# FAULTMUX register map
Vendor: Texas Instruments
Peripheral module from a debugger description file (folder UCD3138R032RSM).
Registers are 32-bit, access per field, no defined reset value unless marked. A register's access mark holds for its fields unless they carry their own. Offsets are as the file gives them; lines under a group give offsets from that group; [hi:lo] are bit positions; {n}, {i} and the like mark numbered series; 'fields as' and 'values as' point back to an identical list; <NAME> marks a mode.

## FAULTMUX (part 1 of 2) — top level module
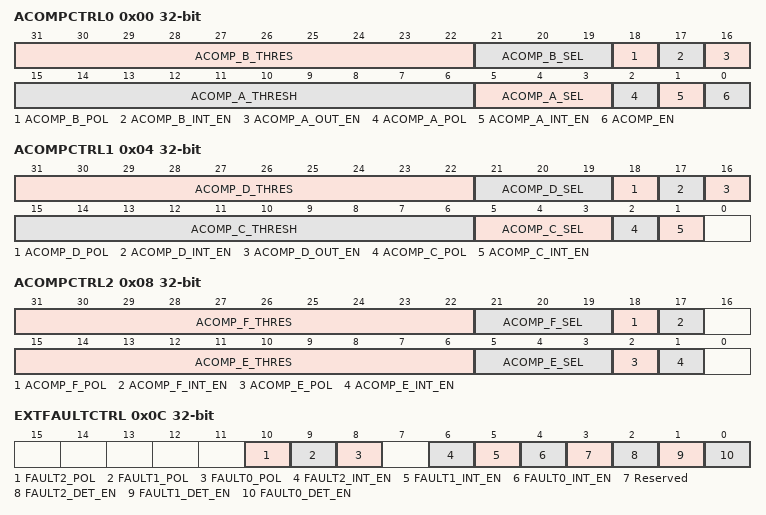
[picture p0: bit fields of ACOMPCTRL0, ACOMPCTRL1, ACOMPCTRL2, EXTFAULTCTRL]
0x00 ACOMPCTRL0 rw — Analog Comparator Control 0 Register
  [31:22] ACOMP_B_THRES — Configures Analog Comparator B Threshold value.Multiplies refernece voltage 19.53125 mV to (ACOMP_B_THRES+1)
  [21:19] ACOMP_B_SEL — Configures Analog Comparator B Threshold
    4=filter2 (Analog Comparator B Threshold set by Filter 2 Output); 3=filter1 (Analog Comparator B Threshold set by Filter 1 Output); 2=filter0 (Analog Comparator B Threshold set by Filter 0 Output); 1=comp_ramp (Analog Comparator B Threshold set by Comparator Ramp 0); 0=Default (Analog Comparator B Threshold set by ACOMP_B_THRESH (Default))
  [18] ACOMP_B_POL — Analog Comparator B Polarity
    1=Above_threshold (Comparator result enabled when input exceeds threshold (Default)); 0=Below_threshold (Comparator result enabled when input falls below threshold)
  [17] ACOMP_B_INT_EN — Analog Comparator B Interrupt Enable
    1=Enables analog comparator B interrupt generation; 0=Disables analog comparator B interrupt generation
  [16] ACOMP_A_OUT_EN — Analog Comparator A DAC Output Enable
    1=Enables output of comparator DAC A onto EAP2 pin; 0=Disables output of comparator DAC A onto EAP2 pin
  [15:6] ACOMP_A_THRESH — Configures Analog Comparator A Threshold value.Multiplies refernece voltage 19.53125 mV to (ACOMP_B_THRES+1)
  [5:3] ACOMP_A_SEL — Configures Analog Comparator A Threshold
    4=filter2 (Analog Comparator A Threshold set by Filter 2 Output); 3=filter1 (Analog Comparator A Threshold set by Filter 1 Output); 2=filter0 (Analog Comparator A Threshold set by Filter 0 Output); 1=comp_ramp (Analog Comparator A Threshold set by Comparator Ramp 0); 0=Default (Analog Comparator A Threshold set by ACOMP_B_THRESH (Default))
  [2] ACOMP_A_POL — Analog Comparator A Polarity
    values as ACOMP_B_POL
  [1] ACOMP_A_INT_EN — Analog Comparator A Interrupt Enable
    1=Enables Analog Comparator A Interrupt generation; 0=diable (Disables Analog Comparator A Interrupt generation (Default))
  [0] ACOMP_EN — Analog Comparators Enable
    1=enable (Analog Comparators Enabled); 0=diable (Analog Comparators Disabled (Default))
0x04 ACOMPCTRL1 — Analog Comparator Control 1 Register
  [31:22] ACOMP_D_THRES rw — Configures Analog Comparator D Threshold value.Multiplies refernece voltage 19.53125 mV to (ACOMP_B_THRES+1)
  [21:19] ACOMP_D_SEL rw — Configures Analog Comparator D Threshold
    4=filter2 (Analog Comparator D Threshold set by Filter 2 Output); 3=filter1 (Analog Comparator D Threshold set by Filter 1 Output); 2=filter0 (Analog Comparator D Threshold set by Filter 0 Output); 1=comp_ramp (Analog Comparator D Threshold set by Comparator Ramp 0); 0=Default (Analog Comparator D Threshold set by ACOMP_D_THRESH (Default))
  [18] ACOMP_D_POL rw — Analog Comparator D Polarity
    values as ACOMPCTRL0.ACOMP_B_POL
  [17] ACOMP_D_INT_EN rw — Analog Comparator D Interrupt Enable
    1=Enables Analog Comparator D Interrupt generation; 0=diable (Disables Analog Comparator D Interrupt generation (Default))
  [16] ACOMP_D_OUT_EN rw — Analog Comparator D DAC Output Enable
    1=Enables output of Comparator DAC D onto AD pin; 0== Disables output of Comparator DAC D onto AD pin (Default)
  [15:6] ACOMP_C_THRESH rw — Configures Analog Comparator C Threshold value.Multiplies refernece voltage 19.53125 mV to (ACOMP_C_THRES+1)
  [5:3] ACOMP_C_SEL rw — Configures Analog Comparator C Threshold
    4=filter2 (Analog Comparator C Threshold set by Filter 2 Output); 3=filter1 (Analog Comparator C Threshold set by Filter 1 Output); 2=filter0 (Analog Comparator C Threshold set by Filter 0 Output); 1=comp_ramp (Analog Comparator C Threshold set by Comparator Ramp 0); 0=Default (Analog Comparator C Threshold set by ACOMP_C_THRESH (Default))
  [2] ACOMP_C_POL rw — Analog Comparator C Polarity
    values as ACOMPCTRL0.ACOMP_B_POL
  [1] ACOMP_C_INT_EN rw — Analog Comparator C Interrupt Enable
    1=Enables Analog Comparator C Interrupt generation; 0=diable (Disables Analog Comparator C Interrupt generation (Default))
0x08 ACOMPCTRL2 — Analog Comparator Control 1 Register
  [31:22] ACOMP_F_THRES rw — Configures Analog Comparator F Threshold value.Multiplies refernece voltage 19.53125 mV to (ACOMP_F_THRES+1)
    1=refrence_voltage_2 (= Comparator Reference of 39.0625 mV); 0=refrence_voltage (= Comparator Reference of 19.53125 mV)
  [21:19] ACOMP_F_SEL rw — Configures Analog Comparator F Threshold
    5=AD05_pin (Reference driven from AD05 pin instead of DAC); 4=filter2 (Analog Comparator F Threshold set by Filter 2 Output); 3=filter1 (Analog Comparator F Threshold set by Filter 1 Output); 2=filter0 (Analog Comparator F Threshold set by Filter 0 Output); 1=comp_ramp (Analog Comparator F Threshold set by Comparator Ramp 0); 0=Default (Analog Comparator F Threshold set by ACOMP_F_THRESH (Default))
  [18] ACOMP_F_POL rw — Analog Comparator F Polarity
    values as ACOMPCTRL0.ACOMP_B_POL
  [17] ACOMP_F_INT_EN rw — Analog Comparator F Interrupt Enable
    1=Enables Analog Comparator F Interrupt generation; 0=diable (Disables Analog Comparator F Interrupt generation (Default))
  [15:6] ACOMP_E_THRES rw — Configures Analog Comparator E Threshold value.Multiplies refernece voltage 19.53125 mV to (ACOMP_E_THRES+1)
    values as ACOMP_F_THRES
  [5:3] ACOMP_E_SEL rw — Configures Analog Comparator E Threshold
    4=filter2 (Analog Comparator E Threshold set by Filter 2 Output); 3=filter1 (Analog Comparator E Threshold set by Filter 1 Output); 2=filter0 (Analog Comparator E Threshold set by Filter 0 Output); 1=comp_ramp (Analog Comparator E Threshold set by Comparator Ramp 0); 0=Default (Analog Comparator E Threshold set by ACOMP_E_THRESH (Default))
  [2] ACOMP_E_POL rw — Analog Comparator E Polarity
    values as ACOMPCTRL0.ACOMP_B_POL
  [1] ACOMP_E_INT_EN rw — Analog Comparator E Interrupt Enable
    1=Enables Analog Comparator E Interrupt generation; 0=diable (Disables Analog Comparator E Interrupt generation (Default))
0x0C EXTFAULTCTRL — External Fault Control Register
  [10] FAULT2_POL rw — Polarity configuration for FAULT[2] pin
    1=rising (Fault detection enabled on rising edge (Default)); 0=falling (Fault detection enabled on falling edg)
  [9] FAULT1_POL rw — Polarity configuration for FAULT[1] pin
    values as FAULT2_POL
  [8] FAULT0_POL rw — Polarity configuration for FAULT[0] pin
    values as FAULT2_POL
  [6] FAULT2_INT_EN rw — FAULT[2] Pin Interrupt Enable
    1=Enables Fault Detection Interrupt generation; 0=Disables Fault Detection Interrupt generation (Default)
  [5] FAULT1_INT_EN rw — FAULT[1] Pin Interrupt Enable
    values as FAULT2_INT_EN
  [4] FAULT0_INT_EN rw — FAULT[0] Pin Interrupt Enable
    values as FAULT2_INT_EN
  [3] Reserved ro — FAULT[3] Pin Detection Enable
    1=enable (Fault Detection Enabled); 0=disable (Fault Detection Disabled (Default))
  [2] FAULT2_DET_EN rw — FAULT[2] Pin Detection Enable
    values as Reserved
  [1] FAULT1_DET_EN rw — FAULT[1] Pin Detection Enable
    values as Reserved
  [0] FAULT0_DET_EN rw — FAULT[0] Pin Detection Enable
    values as Reserved
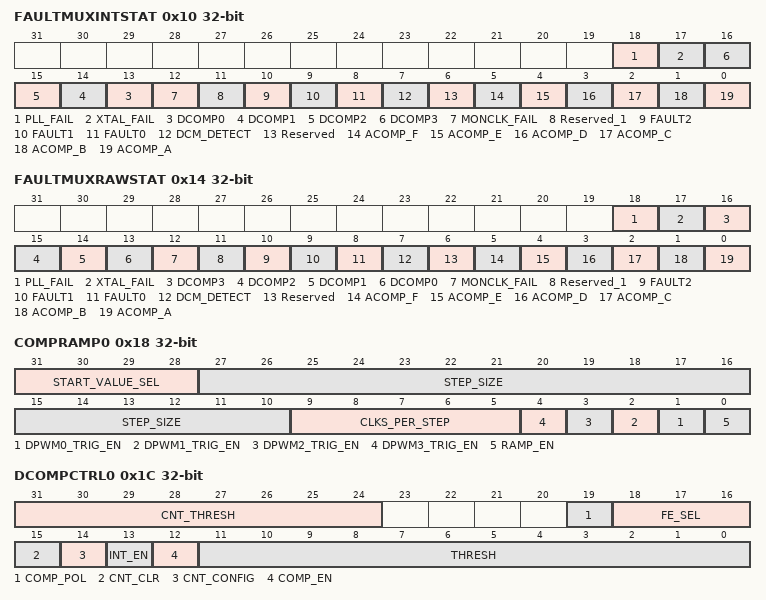
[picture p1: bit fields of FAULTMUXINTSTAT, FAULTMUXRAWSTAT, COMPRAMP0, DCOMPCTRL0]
0x10 FAULTMUXINTSTAT ro — Fault Mux Interrupt Status Register
  [18] PLL_FAIL
    1=detected (PLL failure detected); 0=undetected (PLL failure not detected)
  [17] XTAL_FAIL
    1=detected (XTAL failure detected); 0=notdetected (XTAL failure not detected)
  [n+13] DCOMP{n} (n=0..3) — Digital Comparator {n} Interrupt Status, cleared by read of status register
    1=active (Comparator threshold interrupt active); 0=inactive (Comparator threshold interrupt inactive)
  [12] MONCLK_FAIL — Monitor Oscillator Failure Interrupt Status, cleared by read of status register
    1=failure (Low Frequency Oscillator failure detected); 0=operational (Low Frequency Oscillator operational)
  [11] Reserved_1 — External FAULT[3] Interrupt Detection
    1=found (External GPIO detection found); 0=notfound (No External GPIO detection found)
  [10] FAULT2 — External FAULT[2] Interrupt Detection
    values as Reserved_1
  [9] FAULT1 — External FAULT[1] Interrupt Detection
    values as Reserved_1
  [8] FAULT0 — External FAULT[0] Interrupt Detection
    values as Reserved_1
  [7] DCM_DETECT — Discontinuous Conduction Mode Interrupt Status, cleared by read of status registe
    1=notdetcted (Discontinuous Conduction Mode not detected); 0=detected (Discontinuous Conduction Mode detected)
  [6] Reserved — Analog Comparator G Interrupt Status, cleared by read of status register
    values as DCOMP0
  [5] ACOMP_F — Analog Comparator F Interrupt Status, cleared by read of status register
    values as DCOMP0
  [4] ACOMP_E — Analog Comparator E Interrupt Status, cleared by read of status register
    values as DCOMP0
  [3] ACOMP_D — Analog Comparator D Interrupt Status, cleared by read of status register
    values as DCOMP0
  [2] ACOMP_C — Analog Comparator C Interrupt Status, cleared by read of status register
    values as DCOMP0
  [1] ACOMP_B — Analog Comparator B Interrupt Status, cleared by read of status register
    values as DCOMP0
  [0] ACOMP_A — Analog Comparator A Interrupt Status, cleared by read of status register
    values as DCOMP0
0x14 FAULTMUXRAWSTAT ro — Fault Mux Raw Status Register
  [18] PLL_FAIL — PLL fail raw status
    1=detected (PLL failure detected); 0=notdetected (PLL failure not detected)
  [17] XTAL_FAIL — XTAL fail raw status
    values as FAULTMUXINTSTAT.XTAL_FAIL
  [16] DCOMP3 — Digital Comparator 3 Raw Status
    1=exceeded (Comparator threshold exceeded); 0=notexceeded (Comparator threshold not exceeded)
  [15] DCOMP2 — Digital Comparator 2 Raw Status
    values as DCOMP3
  [14] DCOMP1 — Digital Comparator 2 Raw Status
    values as DCOMP3
  [13] DCOMP0 — Digital Comparator 0 Raw Status
    values as DCOMP3
  [12] MONCLK_FAIL — Monitor Oscillator Failure Raw Status
    1=failure (Monitor Oscillator failure detected); 0=operational (Monitor Oscillator operational)
  [11] Reserved_1 — External Fault Detection on FAULT[3] pin
    1=found (External GPIO detection found); 0=notfound (No External FAULT[3] detection found)
  [10] FAULT2 — External Fault Detection on FAULT[2] pin
    1=found (External GPIO detection found); 0=notfound (No External FAULT[2] detection found)
  [9] FAULT1 — External Fault Detection on FAULT[1] pin
    1=found (External GPIO detection found); 0=notfound (No External FAULT[1] detection found)
  [8] FAULT0 — External Fault Detection on FAULT[8] pin
    1=found (External GPIO detection found); 0=notfound (No External FAULT[8] detection found)
  [7] DCM_DETECT — Discontinuous Conduction Mode Raw Status
    values as FAULTMUXINTSTAT.DCM_DETECT
  [6] Reserved — Analog Comparator G Raw Result
    1=exceeded (Comparator threshold not exceeded); 0=notexceeded (Comparator threshold not exceeded)
  [5] ACOMP_F — Analog Comparator F Raw Result
    values as Reserved
  [4] ACOMP_E — Analog Comparator E Raw Result
    values as Reserved
  [3] ACOMP_D — Analog Comparator D Raw Result
    values as Reserved
  [2] ACOMP_C — Analog Comparator C Raw Result
    values as Reserved
  [1] ACOMP_B — Analog Comparator B Raw Result
    values as Reserved
  [0] ACOMP_A — Analog Comparator A Raw Result
    values as Reserved
0x18 COMPRAMP0 rw — Comparator Ramp Control 0 Register
  [31:28] START_VALUE_SEL — Configures comparator ramp starting value
    9=acomp_G (Analog Comparator Threshold G Value); 8=acomp_F (Analog Comparator Threshold F Value); 7=acomp_E (Analog Comparator Threshold E Value); 6=acomp_D (Analog Comparator Threshold D Value); 5=acomp_C (Analog Comparator Threshold C Value); 4=acomp_B (Analog Comparator Threshold B Value); 3=acomp_A (Analog Comparator Threshold A Value); 2=filter2 (Filter 1 Output (Bits 17-11)); 1=Filter 1 Output (Bits 17-11); 0=FILTER0 (Filter 0 Output (Bits 17-11) (Default))
  [27:10] STEP_SIZE — Programmable 18-bit unsigned comparator step with Bits 27:24 representing the integer portion of the comparator step (0-15 Comparator steps of 19.5mV each) and Bits 23:10 representing the fractional portion of the comparator step
  [9:5] CLKS_PER_STEP — Selects number of ICLK or (ICLK/2) clock cycles per comparator step where number of subcycles can vary from 1 to 32
  [n+1] DPWM{n}_TRIG_EN (n=0..3) — Enables DPWM Trigger from DPWM {n} to Analog Comparator Ramp 0
    1=routed (DPWM {n} trigger routed to Analog Comparator Ramp 0); 0=not_routed (DPWM {n} trigger not routed to Analog Comparator Ramp 0 (Default))
  [0] RAMP_EN — Enable for Analog Comparator Ramp 0
    1=enable (Analog Comparator Ramp enabled); 0=disabled (Analog Comparator Ramp disabled (Default))
0x1C DCOMPCTRL0 — Digital Comparator Control 0 Register
  [31:24] CNT_THRESH rw — Sets the number of received comparator events before declaring a fault
  [19] COMP_POL rw — Digital Comparator 0 Polarity
    1=above (Digital Comparator result asserted if value above threshold (Default)); 0=below (Digital Comparator result asserted if value below threshold (Default))
  [18:16] FE_SEL rw — Selects which Front End absolute data is used for Digital Comparison with threshold
    5=Front End 2 error data selected; 4=Front End 1 error data selected; 3=Front End 0 error data selected; 2=Front End 2 absolute data selected; 1=Front End 1 absolute data selected; 0=Front End 0 absolute data selected (Default)
  [15] CNT_CLR rw — Comparator Detection Counter clear
    1=Clear Comparator Detection counter and associated fault; 0=No clear of Comparator Detection Counter (Default)
  [14] CNT_CONFIG rw — Comparator Detection Counter configuration
    1=decrements (Counter decrements by 1 upon receipt of sample which does not exceed comparator threshold); 0=clear (Counter clears upon receipt of sample which does not exceed comparator threshold (Default))
  [13] INT_EN rw — Comparator Interrupt Enable
    1=Enables Comparator Interrupt generation; 0=Disables Comparator Interrupt generation (Default)
  [12] COMP_EN rw — Digital Comparator 0 Enable
    1=Enables Digital Comparator 0; 0=Disables Digital Comparator 0 (Default)
  [11:0] THRESH rw — Sets the digital comparator threshold, 12-bit signed value with resolution of 1mV/bit
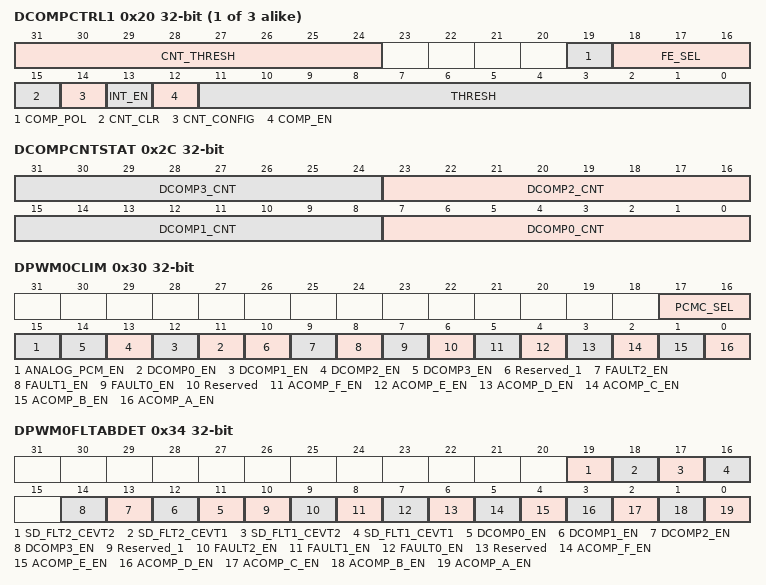
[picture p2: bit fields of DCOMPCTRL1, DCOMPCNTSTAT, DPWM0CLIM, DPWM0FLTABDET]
{0x1C+4i} DCOMPCTRL{i} (i=1..3) — Digital Comparator Control {i} Register
  [31:24] CNT_THRESH rw — Sets the number of received comparator events before declaring a fault
  [19] COMP_POL rw — Digital Comparator {i} Polarity
    values as DCOMPCTRL0.COMP_POL
  [18:16] FE_SEL rw — Selects which Front End absolute data is used for Digital Comparison with threshold
    values as DCOMPCTRL0.FE_SEL
  [15] CNT_CLR rw — Comparator Detection Counter clear
    values as DCOMPCTRL0.CNT_CLR
  [14] CNT_CONFIG rw — Comparator Detection Counter configuration
    values as DCOMPCTRL0.CNT_CONFIG
  [13] INT_EN rw — Comparator Interrupt Enable
    values as DCOMPCTRL0.INT_EN
  [12] COMP_EN rw — Digital Comparator {i} Enable
    1=Enables Digital Comparator {i}; 0=Disables Digital Comparator {i} (Default)
  [11:0] THRESH rw — Sets the digital comparator threshold, 12-bit signed value with resolution of 1.5625mV/bit
0x2C DCOMPCNTSTAT ro — Digital Comparator Counter Status Register
  [8n+7:8n] DCOMP{n}_CNT (n=0..3) — Current value of Digital Comparator {n} detection counter
0x30 DPWM0CLIM — DPWM_0 Current Limit Control Register
  [17:16] PCMC_SEL rw — Selects the PCMC module to trigger PCMC-CBC fault
    2=PCMC3; 1=PCMC2; 0=PCMC1
  [15] ANALOG_PCM_EN rw — Enables Analog Peak Current detection result for DPWM_0 Current Limit
    1=enabled (Analog Peak Current detection enabled for current limit); 0=disabled (Analog Peak Current detection disabled for current limit (Default))
  [n+11] DCOMP{n}_EN rw (n=0..3) — Enables Digital Comparator {n} result for DPWM_0 Current Limit
    values as ANALOG_PCM_EN
  [10] Reserved_1 ro — Enables FAULT[3] pin for DPWM_0 Current Limit
    1=enabled (External Fault pin enabled for current limit); 0=disabled (External Fault pin disabled for current limit (Default))
  [9] FAULT2_EN rw — Enables FAULT[2] pin for DPWM_0 Current Limit
    values as Reserved_1
  [8] FAULT1_EN rw — Enables FAULT[1] pin for DPWM_0 Current Limit
    values as Reserved_1
  [7] FAULT0_EN rw — Enables FAULT[0] pin for DPWM_0 Current Limit
    values as Reserved_1
  [6] Reserved ro — Enables Analog Comparator G result for DPWM_0 Current Limit
    1=enabled (Analog Comparator result enabled for current limit); 0=disabled (Analog Comparator result disabled for current limit (Default))
  [5] ACOMP_F_EN rw — Enables Analog Comparator F result for DPWM_0 Current Limit
    values as Reserved
  [4] ACOMP_E_EN rw — Enables Analog Comparator E result for DPWM_0 Current Limit
    values as Reserved
  [3] ACOMP_D_EN rw — Enables Analog Comparator D result for DPWM_0 Current Limit
    values as Reserved
  [2] ACOMP_C_EN rw — Enables Analog Comparator C result for DPWM_0 Current Limit
    values as Reserved
  [1] ACOMP_B_EN rw — Enables Analog Comparator B result for DPWM_0 Current Limit
    values as Reserved
  [0] ACOMP_A_EN rw — Enables Analog Comparator A result for DPWM_0 Current Limit
    values as Reserved
0x34 DPWM0FLTABDET — DPWM_0 Fault AB Detection Register
  [19] SD_FLT2_CEVT2 rw — Enables SDFM Filter2 Compare Event 2 output for DPWM1 Fault detection
  [18] SD_FLT2_CEVT1 rw — Enables SDFM Filter2 Compare Event 1 output for DPWM1 Fault detection
  [17] SD_FLT1_CEVT2 rw — Enables SDFM Filter1 Compare Event 2 output for DPWM1 Fault detection
  [16] SD_FLT1_CEVT1 rw — Enables SDFM Filter1 Compare Event 1 output for DPWM1 Fault detection
  [n+11] DCOMP{n}_EN rw (n=0..3) — Enables Digital Comparator {n} result for DPWM_0 Fault AB Detection
    1=enable (Digital Comparator {n} result enabled for current limit); 0=disable (Digital Comparator {n} result disabled for current limit (Default))
  [10] Reserved_1 ro — Enables FAULT[3] pin for DPWM_0 Current Limit
    1=enable (External Fault pin enabled for current limit); 0=disable (External Fault pin disabled for current limit (Default))
  [9] FAULT2_EN rw — Enables FAULT[2] pin for DPWM_0 Fault AB Detection
    values as Reserved_1
  [8] FAULT1_EN rw — Enables FAULT[1] pin for DPWM_0 Fault AB Detection
    values as Reserved_1
  [7] FAULT0_EN rw — Enables FAULT[0] pin for DPWM_0 Fault AB Detection
    values as Reserved_1
  [6] Reserved ro — Enables Analog Comparator G result for DPWM_0 Current Limit
    1=enable (Analog Comparator result enabled for current limit); 0=disable (Analog Comparator result disabled for current limit (Default))
  [5] ACOMP_F_EN rw — Enables Analog Comparator F result for DPWM_0 Fault AB Detection
    values as Reserved
  [4] ACOMP_E_EN rw — Enables Analog Comparator E result for DPWM_0 Fault AB Detection
    values as Reserved
  [3] ACOMP_D_EN rw — Enables Analog Comparator D result for DPWM_0 Fault AB Detection
    values as Reserved
  [2] ACOMP_C_EN rw — Enables Analog Comparator C result for DPWM_0 Fault AB Detection
    values as Reserved
  [1] ACOMP_B_EN rw — Enables Analog Comparator B result for DPWM_0 Fault AB Detection
    values as Reserved
  [0] ACOMP_A_EN rw — Enables Analog Comparator A result for DPWM_0 Fault AB Detection
    values as Reserved
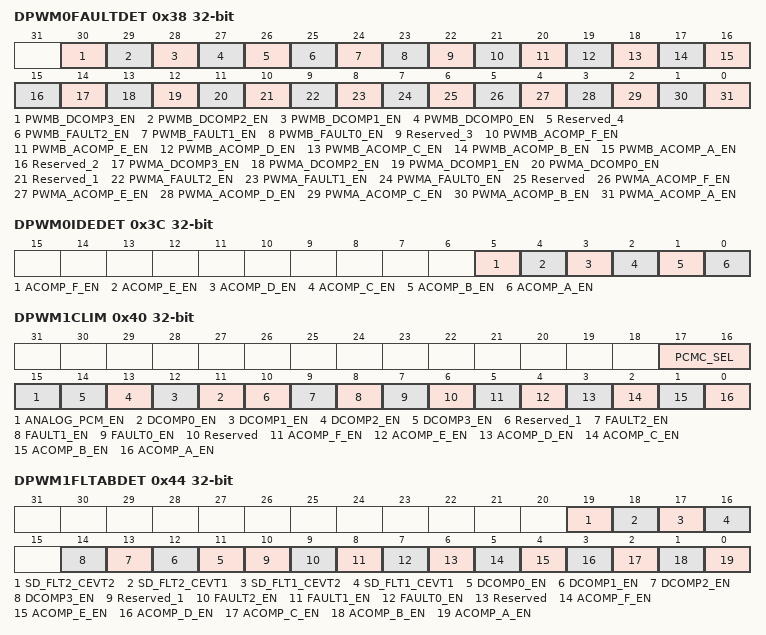
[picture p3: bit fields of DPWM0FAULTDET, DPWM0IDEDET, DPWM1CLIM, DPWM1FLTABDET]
0x38 DPWM0FAULTDET — DPWM 0 Fault Detection Register
  [30] PWMB_DCOMP3_EN rw — Enables Digital Comparator 3 result for DPWM_0 PWM-B Fault Detection
    1=enable (Digital Comparator 3 enabled for fault detection); 0=disbaled (Digital Comparator 3 disabled for fault detection (Default))
  [29] PWMB_DCOMP2_EN rw — Enables Digital Comparator 2 result for DPWM_0 PWM-B Fault Detection
    1=enable (Digital Comparator 2 enabled for fault detection); 0=disbaled (Digital Comparator 2 disabled for fault detection (Default))
  [28] PWMB_DCOMP1_EN rw — Enables Digital Comparator 1 result for DPWM_0 PWM-B Fault Detection
    1=enable (Digital Comparator 1 enabled for fault detection); 0=disbaled (Digital Comparator 1 disabled for fault detection (Default))
  [27] PWMB_DCOMP0_EN rw — Enables Digital Comparator 3 result for DPWM_0 PWM-B Fault Detection
    values as PWMB_DCOMP3_EN
  [26] Reserved_4 ro — Enables FAULT[3] pin for DPWM_0 PWM-B Fault Detection
    1=enable (External Fault pin enabled for fault detection); 0=disbaled (External Fault pin disabled for fault detection (Default))
  [25] PWMB_FAULT2_EN rw — Enables FAULT[2] pin for DPWM_0 PWM-B Fault Detection
    values as Reserved_4
  [24] PWMB_FAULT1_EN rw — Enables FAULT[1] pin for DPWM_0 PWM-B Fault Detection
    values as Reserved_4
  [23] PWMB_FAULT0_EN rw — Enables FAULT[0] pin for DPWM_0 PWM-B Fault Detection
    values as Reserved_4
  [22] Reserved_3 ro — Enables Analog Comparator G result for DPWM_0 PWM-B Fault detection
    1=enable (Analog Comparator result enabled for fault detection); 0=disbaled (Analog Comparator result disabled for fault detection (Default))
  [21] PWMB_ACOMP_F_EN rw — Enables Analog Comparator F result for DPWM_0 PWM-B Fault detection
    values as Reserved_3
  [20] PWMB_ACOMP_E_EN rw — Enables Analog Comparator E result for DPWM_0 PWM-B Fault detection
    values as Reserved_3
  [19] PWMB_ACOMP_D_EN rw — Enables Analog Comparator D result for DPWM_0 PWM-B Fault detection
    values as Reserved_3
  [18] PWMB_ACOMP_C_EN rw — Enables Analog Comparator C result for DPWM_0 PWM-B Fault detection
    values as Reserved_3
  [17] PWMB_ACOMP_B_EN rw — Enables Analog Comparator B result for DPWM_0 PWM-B Fault detection
    values as Reserved_3
  [16] PWMB_ACOMP_A_EN rw — Enables Analog Comparator A result for DPWM_0 PWM-B Fault detection
    values as Reserved_3
  [15] Reserved_2 ro — RESEVED
  [14] PWMA_DCOMP3_EN rw — Enables Digital Comparator 3 result for DPWM_0 PWM-A Fault Detection
    values as PWMB_DCOMP3_EN
  [13] PWMA_DCOMP2_EN rw — Enables Digital Comparator 2 result for DPWM_0 PWM-A Fault Detection
    values as PWMB_DCOMP2_EN
  [12] PWMA_DCOMP1_EN rw — Enables Digital Comparator 1 result for DPWM_0 PWM-A Fault Detection
    values as PWMB_DCOMP1_EN
  [11] PWMA_DCOMP0_EN rw — Enables Digital Comparator 3 result for DPWM_0 PWM-A Fault Detection
    values as PWMB_DCOMP3_EN
  [10] Reserved_1 ro — Enables FAULT[3] pin for DPWM_0 PWM-A Fault Detection
    values as Reserved_4
  [9] PWMA_FAULT2_EN rw — Enables FAULT[2] pin for DPWM_0 PWM-A Fault Detection
    values as Reserved_4
  [8] PWMA_FAULT1_EN rw — Enables FAULT[1] pin for DPWM_0 PWM-A Fault Detection
    values as Reserved_4
  [7] PWMA_FAULT0_EN rw — Enables FAULT[0] pin for DPWM_0 PWM-A Fault Detection
    values as Reserved_4
  [6] Reserved ro — Enables Analog Comparator G result for DPWM_0 PWM-A Fault detection
    values as Reserved_3
  [5] PWMA_ACOMP_F_EN rw — Enables Analog Comparator F result for DPWM_0 PWM-A Fault detection
    values as Reserved_3
  [4] PWMA_ACOMP_E_EN rw — Enables Analog Comparator E result for DPWM_0 PWM-A Fault detection
    values as Reserved_3
  [3] PWMA_ACOMP_D_EN rw — Enables Analog Comparator D result for DPWM_0 PWM-A Fault detection
    values as Reserved_3
  [2] PWMA_ACOMP_C_EN rw — Enables Analog Comparator C result for DPWM_0 PWM-A Fault detection
    values as Reserved_3
  [1] PWMA_ACOMP_B_EN rw — Enables Analog Comparator B result for DPWM_0 PWM-A Fault detection
    values as Reserved_3
  [0] PWMA_ACOMP_A_EN rw — Enables Analog Comparator A result for DPWM_0 PWM-A Fault detection
    values as Reserved_3
0x3C DPWM0IDEDET access not given — DPWM 0 IDE detection register
  [all] fields
    1=enable; 0=disable
  [5] ACOMP_F_EN — Enables Analog Comparator F result for DPWM0 IDE detection
  [4] ACOMP_E_EN — Enables Analog Comparator E result for DPWM0 IDE detection
  [3] ACOMP_D_EN — Enables Analog Comparator D result for DPWM0 IDE detection
  [2] ACOMP_C_EN — Enables Analog Comparator C result for DPWM0 IDE detection
  [1] ACOMP_B_EN — Enables Analog Comparator B result for DPWM0 IDE detection
  [0] ACOMP_A_EN — Enables Analog Comparator A result for DPWM0 IDE detection
0x40 DPWM1CLIM access not given — DPWM 1 Current Limit Control Register
  [17:16] PCMC_SEL — Selects the PCMC module to trigger PCMC- CBC fault
    2=PCMC3; 1=PCMC2; 0=PCMC1
  [15] ANALOG_PCM_EN rw — Enables Analog Peak Current detection result for DPWM_1 Current Limit
    values as DPWM0CLIM.ANALOG_PCM_EN
  [n+11] DCOMP{n}_EN rw (n=0..3) — Enables Digital Comparator {n} result for DPWM_1 Current Limit
    values as DPWM0CLIM.ANALOG_PCM_EN
  [10] Reserved_1 ro — Enables FAULT[3] pin for DPWM_1 Current Limit
    values as DPWM0CLIM.Reserved_1
  [9] FAULT2_EN rw — Enables FAULT[2] pin for DPWM_1 Current Limit
    values as DPWM0CLIM.Reserved_1
  [8] FAULT1_EN rw — Enables FAULT[1] pin for DPWM_1 Current Limit
    values as DPWM0CLIM.Reserved_1
  [7] FAULT0_EN rw — Enables FAULT[0] pin for DPWM_1 Current Limit
    values as DPWM0CLIM.Reserved_1
  [6] Reserved ro — Enables Analog Comparator G result for DPWM_1 Current Limit
    values as DPWM0CLIM.Reserved
  [5] ACOMP_F_EN rw — Enables Analog Comparator F result for DPWM_1 Current Limit
    values as DPWM0CLIM.Reserved
  [4] ACOMP_E_EN rw — Enables Analog Comparator E result for DPWM_1 Current Limit
    values as DPWM0CLIM.Reserved
  [3] ACOMP_D_EN rw — Enables Analog Comparator D result for DPWM_1 Current Limit
    values as DPWM0CLIM.Reserved
  [2] ACOMP_C_EN rw — Enables Analog Comparator C result for DPWM_1 Current Limit
    values as DPWM0CLIM.Reserved
  [1] ACOMP_B_EN rw — Enables Analog Comparator B result for DPWM_1 Current Limit
    values as DPWM0CLIM.Reserved
  [0] ACOMP_A_EN rw — Enables Analog Comparator A result for DPWM_1 Current Limit
    values as DPWM0CLIM.Reserved
0x44 DPWM1FLTABDET — DPWM_1 Fault AB Detection Register
  [19] SD_FLT2_CEVT2 rw — Enables SDFM Filter2 Compare Event 2 output for DPWM0 Fault detection
  [18] SD_FLT2_CEVT1 rw — Enables SDFM Filter2 Compare Event 1 output for DPWM0 Fault detection
  [17] SD_FLT1_CEVT2 rw — Enables SDFM Filter1 Compare Event 2 output for DPWM0 Fault detection
  [16] SD_FLT1_CEVT1 rw — Enables SDFM Filter1 Compare Event 1 output for DPWM0 Fault detection
  [n+11] DCOMP{n}_EN rw (n=0..3) — Enables Digital Comparator {n} result for DPWM_1 Fault AB Detection
    values as DPWM0FLTABDET.DCOMP0_EN
  [10] Reserved_1 ro — Enables FAULT[3] pin for DPWM_1 Current Limit
    values as DPWM0FLTABDET.Reserved_1
  [9] FAULT2_EN rw — Enables FAULT[2] pin for DPWM_1 Fault AB Detection
    values as DPWM0FLTABDET.Reserved_1
  [8] FAULT1_EN rw — Enables FAULT[1] pin for DPWM_1 Fault AB Detection
    values as DPWM0FLTABDET.Reserved_1
  [7] FAULT0_EN rw — Enables FAULT[0] pin for DPWM_1 Fault AB Detection
    values as DPWM0FLTABDET.Reserved_1
  [6] Reserved ro — Enables Analog Comparator G result for DPWM_1 Current Limit
    values as DPWM0FLTABDET.Reserved
  [5] ACOMP_F_EN rw — Enables Analog Comparator F result for DPWM_1 Fault AB Detection
    values as DPWM0FLTABDET.Reserved
  [4] ACOMP_E_EN rw — Enables Analog Comparator E result for DPWM_1 Fault AB Detection
    values as DPWM0FLTABDET.Reserved
  [3] ACOMP_D_EN rw — Enables Analog Comparator D result for DPWM_1 Fault AB Detection
    values as DPWM0FLTABDET.Reserved
  [2] ACOMP_C_EN rw — Enables Analog Comparator C result for DPWM_1 Fault AB Detection
    values as DPWM0FLTABDET.Reserved
  [1] ACOMP_B_EN rw — Enables Analog Comparator B result for DPWM_1 Fault AB Detection
    values as DPWM0FLTABDET.Reserved
  [0] ACOMP_A_EN rw — Enables Analog Comparator A result for DPWM_1 Fault AB Detection
    values as DPWM0FLTABDET.Reserved
